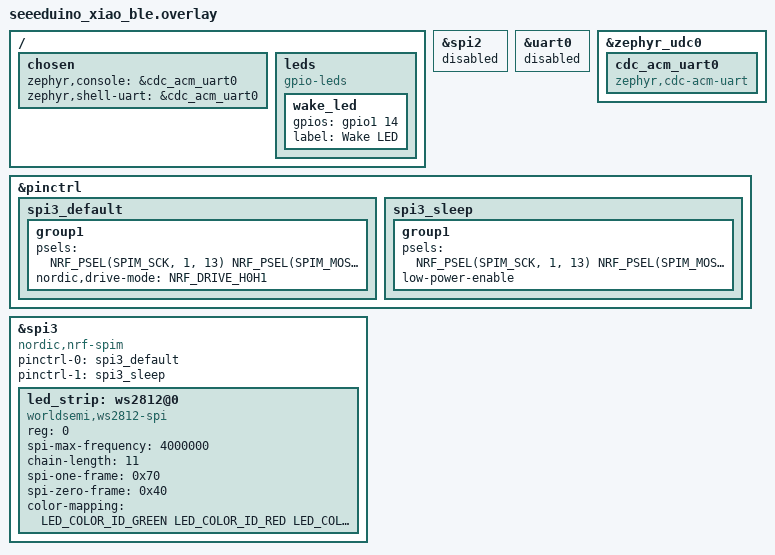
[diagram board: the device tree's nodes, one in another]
#include <dt-bindings/led/led.h>
#include <dt-bindings/gpio/gpio.h>

/*
 * WS2812B LED strip via SPI on the Seeed XIAO nRF52840.
 *
 * Data pin: D10 = P1.15 (SPIM_MOSI on SPI3)
 * Wake LED: D9  = P1.14 (GPIO, active-high)
 *
 * SPI3 uses SCK (P1.13) and MOSI (P1.15) only.
 * D9/MISO freed for the wake/sleep indicator LED.
 *
 * The board's default pinctrl claims P1.13-P1.15 on SPI2,
 * so we disable SPI2 to free the pins.
 */

/* Disable SPI2 which shares P1.13-P1.15 with our SPI3 config */
&spi2 {
    status = "disabled";
};

/* Disable UART0 which claims D6 (P1.11 TX) and D7 (P1.12 RX) by default */
&uart0 {
    status = "disabled";
};

/ {
    chosen {
        zephyr,console = &cdc_acm_uart0;
        zephyr,shell-uart = &cdc_acm_uart0;
    };
};

&zephyr_udc0 {
    cdc_acm_uart0: cdc_acm_uart0 {
        compatible = "zephyr,cdc-acm-uart";
    };
};

&pinctrl {
    spi3_default: spi3_default {
        group1 {
            psels = <NRF_PSEL(SPIM_SCK, 1, 13)
                     NRF_PSEL(SPIM_MOSI, 1, 15)>;
            nordic,drive-mode = <NRF_DRIVE_H0H1>;
        };
    };

    spi3_sleep: spi3_sleep {
        group1 {
            psels = <NRF_PSEL(SPIM_SCK, 1, 13)
                     NRF_PSEL(SPIM_MOSI, 1, 15)>;
            low-power-enable;
        };
    };
};

&spi3 {
    compatible = "nordic,nrf-spim";
    status = "okay";

    pinctrl-0 = <&spi3_default>;
    pinctrl-1 = <&spi3_sleep>;
    pinctrl-names = "default", "sleep";

    led_strip: ws2812@0 {
        compatible = "worldsemi,ws2812-spi";

        /* SPI */
        reg = <0>; /* ignored, but necessary for SPI bindings */
        spi-max-frequency = <4000000>;

        /* WS2812 timing at 4MHz SPI clock:
         * 0x70 = 0111 0000 → T1H = 750ns (WS2812B needs ≥580ns)
         * 0x40 = 0100 0000 → T0H = 250ns (WS2812B needs ≤380ns)
         * Previous 0x60 gave T0H=500ns which exceeds the threshold,
         * causing all bits to be read as 1 → white on all LEDs. */
        chain-length = <11>; /* 3 battery LEDs + 8 key LEDs */
        spi-one-frame = <0x70>;
        spi-zero-frame = <0x40>;

        color-mapping = <LED_COLOR_ID_GREEN
                         LED_COLOR_ID_RED
                         LED_COLOR_ID_BLUE>;
    };
};

/* Wake/sleep indicator LED on D9 = P1.14 (freed from SPI3 MISO) */
/ {
    leds {
        compatible = "gpio-leds";
        wake_led: wake_led {
            gpios = <&gpio1 14 GPIO_ACTIVE_HIGH>;
            label = "Wake LED";
        };
    };
};
